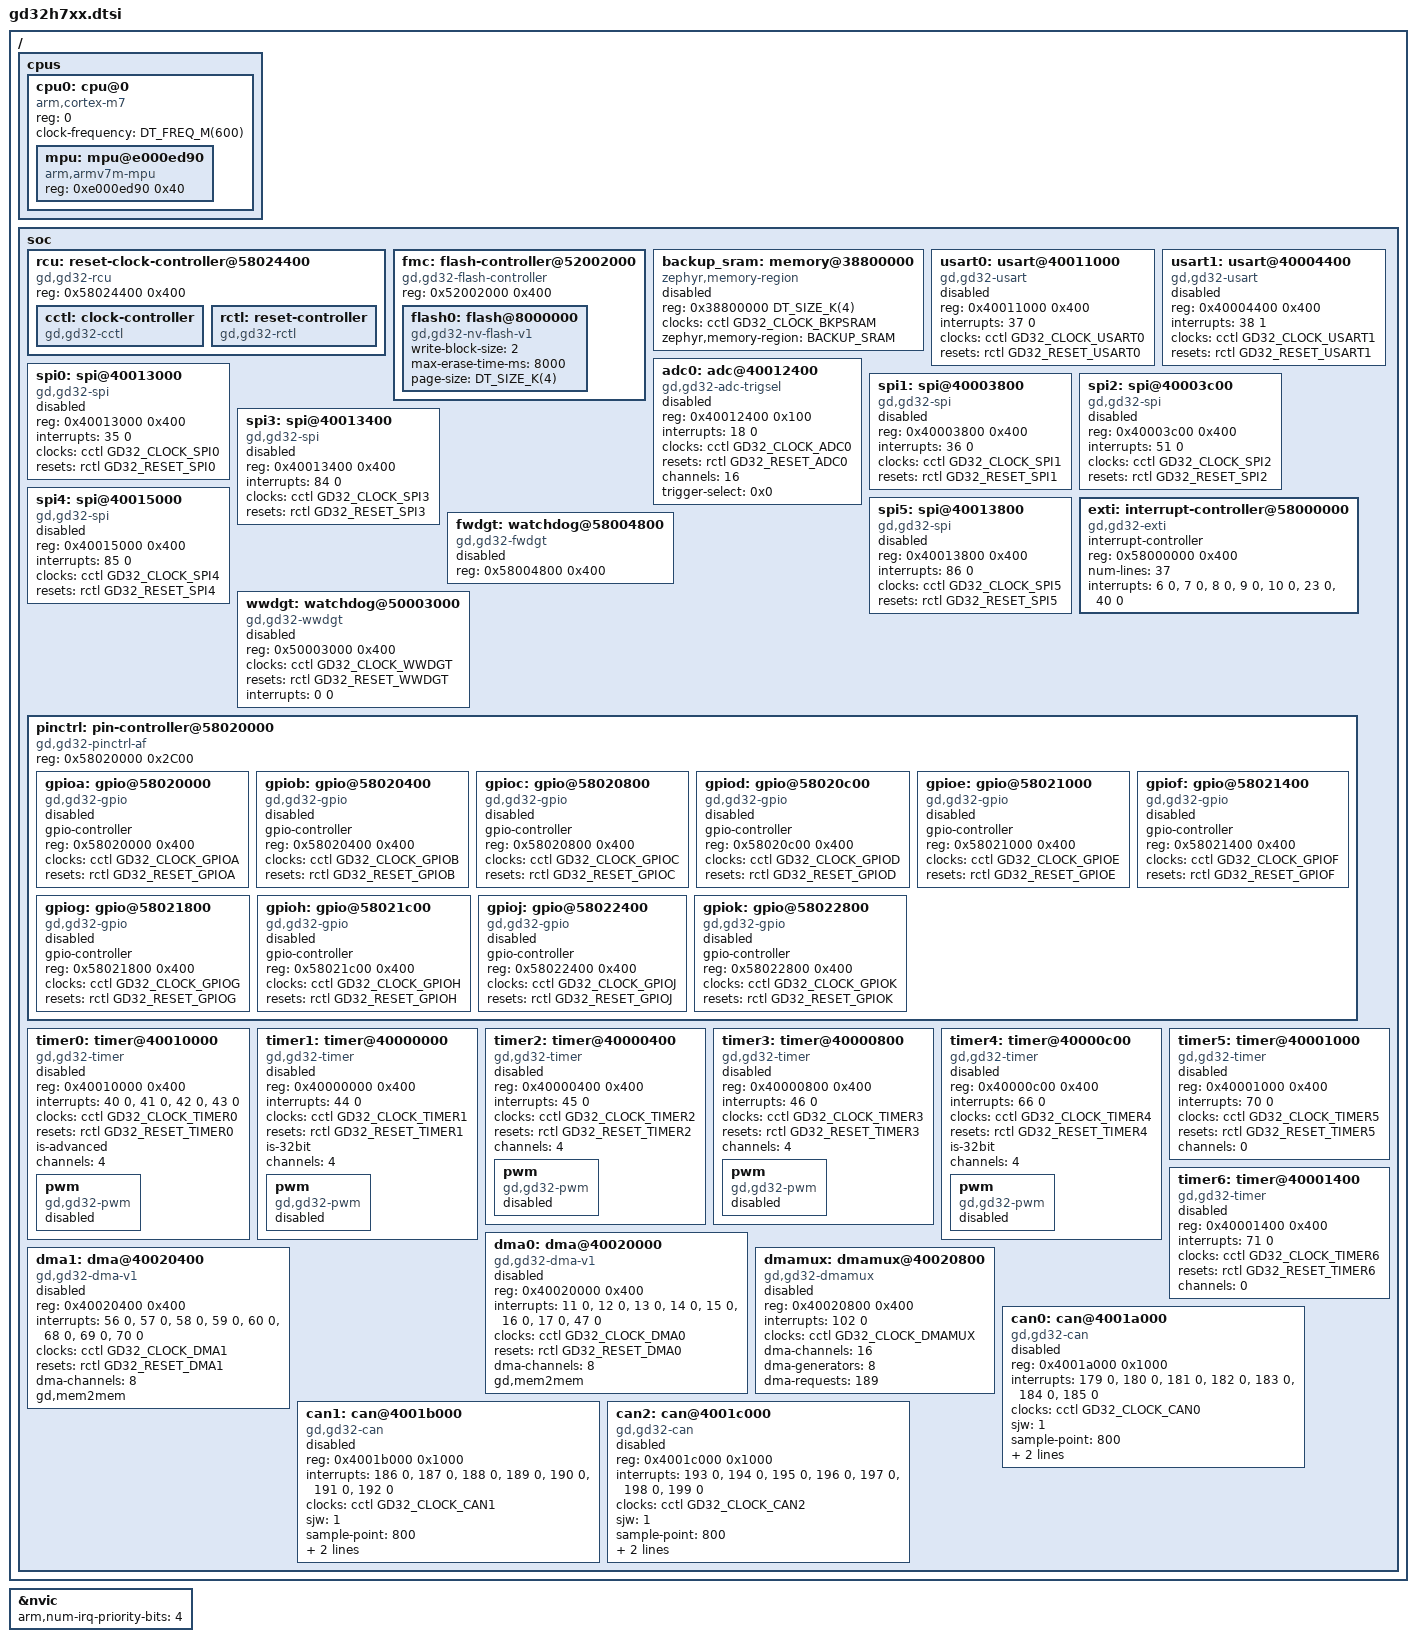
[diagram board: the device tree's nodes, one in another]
/*
 * Copyright (c) 2026 GigaDevice Semiconductor Inc.
 *
 * SPDX-License-Identifier: Apache-2.0
 */

#include <freq.h>
#include <arm/armv7-m.dtsi>
#include <zephyr/dt-bindings/gpio/gpio.h>
#include <zephyr/dt-bindings/i2c/i2c.h>
#include <zephyr/dt-bindings/pwm/pwm.h>
#include <zephyr/dt-bindings/clock/gd32h7xx-clocks.h>
#include <zephyr/dt-bindings/reset/gd32h7xx.h>
/ {
	cpus {
		#address-cells = <1>;
		#size-cells = <0>;

		cpu0: cpu@0 {
			compatible = "arm,cortex-m7";
			reg = <0>;
			#address-cells = <1>;
			#size-cells = <1>;
			clock-frequency = <DT_FREQ_M(600)>;

			mpu: mpu@e000ed90 {
				compatible = "arm,armv7m-mpu";
				reg = <0xe000ed90 0x40>;
			};
		};
	};

	soc {
		rcu: reset-clock-controller@58024400 {
			compatible = "gd,gd32-rcu";
			reg = <0x58024400 0x400>;
			status = "okay";

			cctl: clock-controller {
				compatible = "gd,gd32-cctl";
				#clock-cells = <1>;
				status = "okay";
			};

			rctl: reset-controller {
				compatible = "gd,gd32-rctl";
				#reset-cells = <1>;
				status = "okay";
			};
		};

		fmc: flash-controller@52002000 {
			compatible = "gd,gd32-flash-controller";
			reg = <0x52002000 0x400>;

			#address-cells = <1>;
			#size-cells = <1>;

			flash0: flash@8000000 {
				compatible = "gd,gd32-nv-flash-v1", "soc-nv-flash";
				write-block-size = <2>;
				max-erase-time-ms = <8000>;
				page-size = <DT_SIZE_K(4)>;
			};
		};

		backup_sram: memory@38800000 {
			compatible = "zephyr,memory-region", "gd,gd32-backup-sram";
			reg = <0x38800000 DT_SIZE_K(4)>;
			clocks = <&cctl GD32_CLOCK_BKPSRAM>;
			zephyr,memory-region = "BACKUP_SRAM";
			status = "disabled";
		};

		usart0: usart@40011000 {
			compatible = "gd,gd32-usart";
			reg = <0x40011000 0x400>;
			interrupts = <37 0>;
			clocks = <&cctl GD32_CLOCK_USART0>;
			resets = <&rctl GD32_RESET_USART0>;
			status = "disabled";
		};

		usart1: usart@40004400 {
			compatible = "gd,gd32-usart";
			reg = <0x40004400 0x400>;
			interrupts = <38 1>;
			clocks = <&cctl GD32_CLOCK_USART1>;
			resets = <&rctl GD32_RESET_USART1>;
			status = "disabled";
		};

		adc0: adc@40012400 {
			compatible = "gd,gd32-adc-trigsel", "gd,gd32-adc";
			reg = <0x40012400 0x100>;
			interrupts = <18 0>;
			clocks = <&cctl GD32_CLOCK_ADC0>;
			resets = <&rctl GD32_RESET_ADC0>;
			channels = <16>;
			status = "disabled";
			#io-channel-cells = <1>;
			trigger-select = <0x0>;
		};

		spi0: spi@40013000 {
			compatible = "gd,gd32-spi";
			reg = <0x40013000 0x400>;
			interrupts = <35 0>;
			clocks = <&cctl GD32_CLOCK_SPI0>;
			resets = <&rctl GD32_RESET_SPI0>;
			status = "disabled";
			#address-cells = <1>;
			#size-cells = <0>;
		};

		spi1: spi@40003800 {
			compatible = "gd,gd32-spi";
			reg = <0x40003800 0x400>;
			interrupts = <36 0>;
			clocks = <&cctl GD32_CLOCK_SPI1>;
			resets = <&rctl GD32_RESET_SPI1>;
			status = "disabled";
			#address-cells = <1>;
			#size-cells = <0>;
		};

		spi2: spi@40003c00 {
			compatible = "gd,gd32-spi";
			reg = <0x40003c00 0x400>;
			interrupts = <51 0>;
			clocks = <&cctl GD32_CLOCK_SPI2>;
			resets = <&rctl GD32_RESET_SPI2>;
			status = "disabled";
			#address-cells = <1>;
			#size-cells = <0>;
		};

		spi3: spi@40013400 {
			compatible = "gd,gd32-spi";
			reg = <0x40013400 0x400>;
			interrupts = <84 0>;
			clocks = <&cctl GD32_CLOCK_SPI3>;
			resets = <&rctl GD32_RESET_SPI3>;
			status = "disabled";
			#address-cells = <1>;
			#size-cells = <0>;
		};

		spi4: spi@40015000 {
			compatible = "gd,gd32-spi";
			reg = <0x40015000 0x400>;
			interrupts = <85 0>;
			clocks = <&cctl GD32_CLOCK_SPI4>;
			resets = <&rctl GD32_RESET_SPI4>;
			status = "disabled";
			#address-cells = <1>;
			#size-cells = <0>;
		};

		spi5: spi@40013800 {
			compatible = "gd,gd32-spi";
			reg = <0x40013800 0x400>;
			interrupts = <86 0>;
			clocks = <&cctl GD32_CLOCK_SPI5>;
			resets = <&rctl GD32_RESET_SPI5>;
			status = "disabled";
			#address-cells = <1>;
			#size-cells = <0>;
		};

		exti: interrupt-controller@58000000 {
			compatible = "gd,gd32-exti";
			interrupt-controller;
			#interrupt-cells = <1>;
			#address-cells = <0>;
			reg = <0x58000000 0x400>;
			num-lines = <37>;
			interrupts = <6 0>, <7 0>, <8 0>, <9 0>,
				     <10 0>, <23 0>, <40 0>;
			interrupt-names = "line0", "line1", "line2", "line3",
					  "line4", "line5-9", "line10-15";
			status = "okay";
		};

		fwdgt: watchdog@58004800 {
			compatible = "gd,gd32-fwdgt";
			reg = <0x58004800 0x400>;
			status = "disabled";
		};

		wwdgt: watchdog@50003000 {
			compatible = "gd,gd32-wwdgt";
			reg = <0x50003000 0x400>;
			clocks = <&cctl GD32_CLOCK_WWDGT>;
			resets = <&rctl GD32_RESET_WWDGT>;
			interrupts = <0 0>;
			status = "disabled";
		};

	pinctrl: pin-controller@58020000 {
			compatible = "gd,gd32-pinctrl-af";
			reg = <0x58020000 0x2C00>;
			#address-cells = <1>;
			#size-cells = <1>;
			status = "okay";

			gpioa: gpio@58020000 {
				compatible = "gd,gd32-gpio";
				gpio-controller;
				#gpio-cells = <2>;
				reg = <0x58020000 0x400>;
				clocks = <&cctl GD32_CLOCK_GPIOA>;
				resets = <&rctl GD32_RESET_GPIOA>;
				status = "disabled";
			};

			gpiob: gpio@58020400 {
				compatible = "gd,gd32-gpio";
				gpio-controller;
				#gpio-cells = <2>;
				reg = <0x58020400 0x400>;
				clocks = <&cctl GD32_CLOCK_GPIOB>;
				resets = <&rctl GD32_RESET_GPIOB>;
				status = "disabled";
			};

			gpioc: gpio@58020800 {
				compatible = "gd,gd32-gpio";
				gpio-controller;
				#gpio-cells = <2>;
				reg = <0x58020800 0x400>;
				clocks = <&cctl GD32_CLOCK_GPIOC>;
				resets = <&rctl GD32_RESET_GPIOC>;
				status = "disabled";
			};

			gpiod: gpio@58020c00 {
				compatible = "gd,gd32-gpio";
				gpio-controller;
				#gpio-cells = <2>;
				reg = <0x58020c00 0x400>;
				clocks = <&cctl GD32_CLOCK_GPIOD>;
				resets = <&rctl GD32_RESET_GPIOD>;
				status = "disabled";
			};

			gpioe: gpio@58021000 {
				compatible = "gd,gd32-gpio";
				gpio-controller;
				#gpio-cells = <2>;
				reg = <0x58021000 0x400>;
				clocks = <&cctl GD32_CLOCK_GPIOE>;
				resets = <&rctl GD32_RESET_GPIOE>;
				status = "disabled";
			};

			gpiof: gpio@58021400 {
				compatible = "gd,gd32-gpio";
				gpio-controller;
				#gpio-cells = <2>;
				reg = <0x58021400 0x400>;
				clocks = <&cctl GD32_CLOCK_GPIOF>;
				resets = <&rctl GD32_RESET_GPIOF>;
				status = "disabled";
			};

			gpiog: gpio@58021800 {
				compatible = "gd,gd32-gpio";
				gpio-controller;
				#gpio-cells = <2>;
				reg = <0x58021800 0x400>;
				clocks = <&cctl GD32_CLOCK_GPIOG>;
				resets = <&rctl GD32_RESET_GPIOG>;
				status = "disabled";
			};

			gpioh: gpio@58021c00 {
				compatible = "gd,gd32-gpio";
				gpio-controller;
				#gpio-cells = <2>;
				reg = <0x58021c00 0x400>;
				clocks = <&cctl GD32_CLOCK_GPIOH>;
				resets = <&rctl GD32_RESET_GPIOH>;
				status = "disabled";
			};

			gpioj: gpio@58022400 {
				compatible = "gd,gd32-gpio";
				gpio-controller;
				#gpio-cells = <2>;
				reg = <0x58022400 0x400>;
				clocks = <&cctl GD32_CLOCK_GPIOJ>;
				resets = <&rctl GD32_RESET_GPIOJ>;
				status = "disabled";
			};

			gpiok: gpio@58022800 {
				compatible = "gd,gd32-gpio";
				gpio-controller;
				#gpio-cells = <2>;
				reg = <0x58022800 0x400>;
				clocks = <&cctl GD32_CLOCK_GPIOK>;
				resets = <&rctl GD32_RESET_GPIOK>;
				status = "disabled";
			};
		};

		timer0: timer@40010000 {
			compatible = "gd,gd32-timer";
			reg = <0x40010000 0x400>;
			interrupts = <40 0>, <41 0>, <42 0>, <43 0>;
			interrupt-names = "brk", "up", "trgcom", "cc";
			clocks = <&cctl GD32_CLOCK_TIMER0>;
			resets = <&rctl GD32_RESET_TIMER0>;
			is-advanced;
			channels = <4>;
			status = "disabled";

			pwm {
				compatible = "gd,gd32-pwm";
				status = "disabled";
				#pwm-cells = <3>;
			};
		};

		timer1: timer@40000000 {
			compatible = "gd,gd32-timer";
			reg = <0x40000000 0x400>;
			interrupts = <44 0>;
			interrupt-names = "global";
			clocks = <&cctl GD32_CLOCK_TIMER1>;
			resets = <&rctl GD32_RESET_TIMER1>;
			is-32bit;
			channels = <4>;
			status = "disabled";

			pwm {
				compatible = "gd,gd32-pwm";
				status = "disabled";
				#pwm-cells = <3>;
			};
		};

		timer2: timer@40000400 {
			compatible = "gd,gd32-timer";
			reg = <0x40000400 0x400>;
			interrupts = <45 0>;
			interrupt-names = "global";
			clocks = <&cctl GD32_CLOCK_TIMER2>;
			resets = <&rctl GD32_RESET_TIMER2>;
			channels = <4>;
			status = "disabled";

			pwm {
				compatible = "gd,gd32-pwm";
				status = "disabled";
				#pwm-cells = <3>;
			};
		};

		timer3: timer@40000800 {
			compatible = "gd,gd32-timer";
			reg = <0x40000800 0x400>;
			interrupts = <46 0>;
			interrupt-names = "global";
			clocks = <&cctl GD32_CLOCK_TIMER3>;
			resets = <&rctl GD32_RESET_TIMER3>;
			channels = <4>;
			status = "disabled";

			pwm {
				compatible = "gd,gd32-pwm";
				status = "disabled";
				#pwm-cells = <3>;
			};
		};

		timer4: timer@40000c00 {
			compatible = "gd,gd32-timer";
			reg = <0x40000c00 0x400>;
			interrupts = <66 0>;
			interrupt-names = "global";
			clocks = <&cctl GD32_CLOCK_TIMER4>;
			resets = <&rctl GD32_RESET_TIMER4>;
			is-32bit;
			channels = <4>;
			status = "disabled";

			pwm {
				compatible = "gd,gd32-pwm";
				status = "disabled";
				#pwm-cells = <3>;
			};
		};

		timer5: timer@40001000 {
			compatible = "gd,gd32-timer";
			reg = <0x40001000 0x400>;
			interrupts = <70 0>;
			interrupt-names = "global";
			clocks = <&cctl GD32_CLOCK_TIMER5>;
			resets = <&rctl GD32_RESET_TIMER5>;
			channels = <0>;
			status = "disabled";
		};

		timer6: timer@40001400 {
			compatible = "gd,gd32-timer";
			reg = <0x40001400 0x400>;
			interrupts = <71 0>;
			interrupt-names = "global";
			clocks = <&cctl GD32_CLOCK_TIMER6>;
			resets = <&rctl GD32_RESET_TIMER6>;
			channels = <0>;
			status = "disabled";
		};

		dma0: dma@40020000 {
			compatible = "gd,gd32-dma-v1";
			reg = <0x40020000 0x400>;
			interrupts = <11 0>, <12 0>, <13 0>, <14 0>,
				     <15 0>, <16 0>, <17 0>, <47 0>;
			clocks = <&cctl GD32_CLOCK_DMA0>;
			resets = <&rctl GD32_RESET_DMA0>;
			dma-channels = <8>;
			gd,mem2mem;
			#dma-cells = <4>;
			status = "disabled";
		};

		dma1: dma@40020400 {
			compatible = "gd,gd32-dma-v1";
			reg = <0x40020400 0x400>;
			interrupts = <56 0>, <57 0>, <58 0>, <59 0>,
				     <60 0>, <68 0>, <69 0>, <70 0>;
			clocks = <&cctl GD32_CLOCK_DMA1>;
			resets = <&rctl GD32_RESET_DMA1>;
			dma-channels = <8>;
			gd,mem2mem;
			#dma-cells = <4>;
			status = "disabled";
		};

		dmamux: dmamux@40020800 {
			compatible = "gd,gd32-dmamux";
			#dma-cells = <3>;
			reg = <0x40020800 0x400>;
			interrupts = <102 0>;
			clocks = <&cctl GD32_CLOCK_DMAMUX>;
			dma-channels = <16>;
			dma-generators = <8>;
			dma-requests= <189>;
			status = "disabled";
		};

		can0: can@4001a000 {
			compatible = "gd,gd32-can";
			reg = <0x4001a000 0x1000>;
			interrupts = <179 0>, <180 0>, <181 0>, <182 0>,<183 0>, <184 0>, <185 0>;
			interrupt-names = "WAKE_UP", "MESSAGE_BUFFER", "BUS_OFF", "ERROR",
							 "FAST_ERROR", "TX_WARNING", "RX_WARNING";
			clocks = <&cctl GD32_CLOCK_CAN0>;
			status = "disabled";
			sjw = <1>;
			sample-point = <800>;
			sjw-data = <1>;
			sample-point-data = <800>;
		};

		can1: can@4001b000 {
			compatible = "gd,gd32-can";
			reg = <0x4001b000 0x1000>;
			interrupts = <186 0>, <187 0>, <188 0>, <189 0>,<190 0>, <191 0>, <192 0>;
			interrupt-names = "WAKE_UP", "MESSAGE_BUFFER", "BUS_OFF", "ERROR",
							 "FAST_ERROR", "TX_WARNING", "RX_WARNING";
			clocks = <&cctl GD32_CLOCK_CAN1>;
			status = "disabled";
			sjw = <1>;
			sample-point = <800>;
			sjw-data = <1>;
			sample-point-data = <800>;
		};

		can2: can@4001c000 {
			compatible = "gd,gd32-can";
			reg = <0x4001c000 0x1000>;
			interrupts = <193 0>, <194 0>, <195 0>, <196 0>,<197 0>, <198 0>, <199 0>;
			interrupt-names = "WAKE_UP", "MESSAGE_BUFFER", "BUS_OFF", "ERROR",
							 "FAST_ERROR", "TX_WARNING", "RX_WARNING";
			clocks = <&cctl GD32_CLOCK_CAN2>;
			status = "disabled";
			sjw = <1>;
			sample-point = <800>;
			sjw-data = <1>;
			sample-point-data = <800>;
		};
	};
};

&nvic {
	arm,num-irq-priority-bits = <4>;
};
